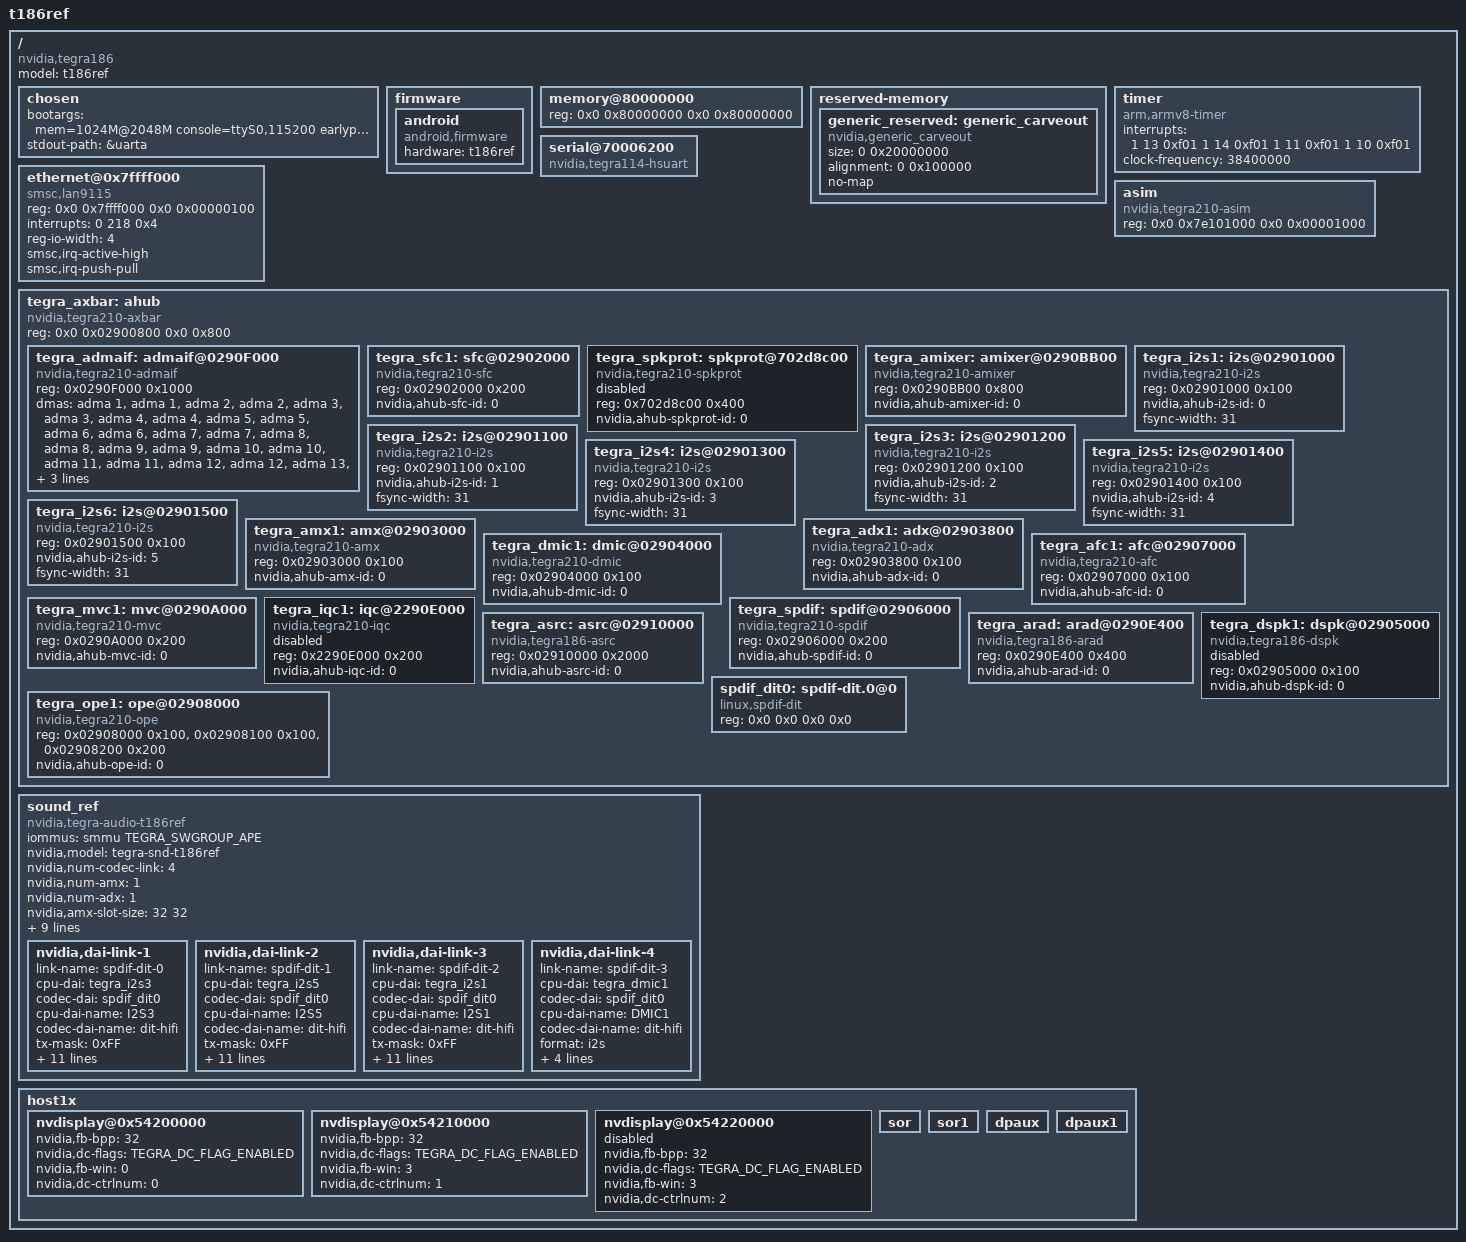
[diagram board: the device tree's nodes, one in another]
/*
 * arch/arm64/boot/dts/tegra186-sim-private.dts
 *
 * Copyright (c) 2014-2015, NVIDIA CORPORATION.  All rights reserved.
 *
 * This program is free software; you can redistribute it and/or modify
 * it under the terms of the GNU General Public License as published by
 * the Free Software Foundation; version 2 of the License.
 *
 * This program is distributed in the hope that it will be useful, but WITHOUT
 * ANY WARRANTY; without even the implied warranty of MERCHANTABILITY or
 * FITNESS FOR A PARTICULAR PURPOSE.  See the GNU General Public License for
 * more details.
 *
 * You should have received a copy of the GNU General Public License along
 * with this program; if not, write to the Free Software Foundation, Inc.,
 * 51 Franklin Street, Fifth Floor, Boston, MA  02110-1301, USA.
 *
 */

/dts-v1/;

/memreserve/ 0x80000000 0x00010000;

#include "tegra186.dtsi"
#include "tegra186-cpus-2D4A.dtsi"
#include "panel-sim.dtsi"
#include "tegra186-sim-hdmi.dtsi"
#include "tegra186-sdhci.dtsi"
#include <dt-bindings/sound/tegra-asoc-alt.h>

/ {
	model = "t186ref";
	compatible = "nvidia,tegra186";

	chosen {
		bootargs ="mem=1024M@2048M console=ttyS0,115200 earlyprintk=uart8250-32bit,0x70006000";
		stdout-path = &uarta;
	};

	/* chosen */

	firmware {
		android {
			compatible = "android,firmware";
			hardware = "t186ref";
		};
	};

	memory@80000000 {
		device_type = "memory";
		reg = < 0x0 0x80000000 0x0 0x80000000 >;
	};

	reserved-memory {
		#address-cells = <2>;
		#size-cells = <2>;
		ranges;

		generic_reserved: generic_carveout {
			compatible = "nvidia,generic_carveout";
			size = <0 0x20000000>;
			alignment = <0 0x100000>;
			no-map;
		};
	};

	timer {
		compatible = "arm,armv8-timer";
		interrupts = <1 13 0xf01
			      1 14 0xf01
			      1 11 0xf01
			      1 10 0xf01>;
		clock-frequency = <38400000>;
	};

	serial@70006200 {
		compatible = "nvidia,tegra114-hsuart";
		status = "okay";
	};

	ethernet@0x7ffff000 {
		compatible = "smsc,lan9115";
		reg = < 0x0 0x7ffff000 0x0 0x00000100 >;
		interrupts = <0 218 0x4>;
		reg-io-width = <4>;
		smsc,irq-active-high;
		smsc,irq-push-pull;
	};

	asim {
		compatible = "nvidia,tegra210-asim";
		reg = < 0x0 0x7e101000 0x0 0x00001000 >;
	};

	tegra_axbar: ahub {
		compatible = "nvidia,tegra210-axbar";
		reg = <0x0 0x02900800 0x0 0x800>;
		status = "okay";

		#address-cells = <1>;
		#size-cells = <1>;
		ranges = <0x02900000 0x0 0x02900000 0x00020000>;

		tegra_admaif: admaif@0290F000 {
			compatible = "nvidia,tegra210-admaif";
			reg = <0x0290F000 0x1000>;
			dmas = <&adma 1>, <&adma 1>, <&adma 2>, <&adma 2>,
				<&adma 3>, <&adma 3>, <&adma 4>, <&adma 4>,
				<&adma 5>, <&adma 5>, <&adma 6>, <&adma 6>,
				<&adma 7>, <&adma 7>, <&adma 8>, <&adma 8>,
				<&adma 9>, <&adma 9>, <&adma 10>, <&adma 10>,
				<&adma 11>, <&adma 11>, <&adma 12>, <&adma 12>,
				<&adma 13>, <&adma 13>, <&adma 14>, <&adma 14>,
				<&adma 15>, <&adma 15>, <&adma 16>, <&adma 16>,
				<&adma 17>, <&adma 17>, <&adma 18>, <&adma 18>,
				<&adma 19>, <&adma 19>, <&adma 20>, <&adma 20>;
			dma-names = "rx1", "tx1", "rx2", "tx2", "rx3", "tx3",
				"rx4", "tx4", "rx5", "tx5", "rx6", "tx6",
				"rx7", "tx7", "rx8", "tx8", "rx9", "tx9",
				"rx10", "tx10", "rx11", "tx11", "rx12", "tx12",
				"rx13", "tx13",	"rx14", "tx14", "rx15", "tx15",
				"rx16", "tx16",	"rx17", "tx17", "rx18", "tx18",
				"rx19", "tx19",	"rx20", "tx20";
			status = "okay";
		};

		tegra_sfc1: sfc@02902000 {
			compatible = "nvidia,tegra210-sfc";
			reg = <0x02902000 0x200>;
			nvidia,ahub-sfc-id = <0>;
			status = "okay";
		};

		tegra_spkprot: spkprot@702d8c00 {
			compatible = "nvidia,tegra210-spkprot";
			reg = <0x702d8c00 0x400>;
			nvidia,ahub-spkprot-id = <0>;
			status = "disabled";
		};

		tegra_amixer: amixer@0290BB00 {
			compatible = "nvidia,tegra210-amixer";
			reg = <0x0290BB00 0x800>;
			nvidia,ahub-amixer-id = <0>;
			status = "okay";
		};

		tegra_i2s1: i2s@02901000 {
			compatible = "nvidia,tegra210-i2s";
			reg = <0x02901000 0x100>;
			nvidia,ahub-i2s-id = <0>;
			status = "okay";
		};

		tegra_i2s2: i2s@02901100 {
			compatible = "nvidia,tegra210-i2s";
			reg = <0x02901100 0x100>;
			nvidia,ahub-i2s-id = <1>;
			status = "okay";
		};

		tegra_i2s3: i2s@02901200 {
			compatible = "nvidia,tegra210-i2s";
			reg = <0x02901200 0x100>;
			nvidia,ahub-i2s-id = <2>;
			status = "okay";
		};

		tegra_i2s4: i2s@02901300 {
			compatible = "nvidia,tegra210-i2s";
			reg = <0x02901300 0x100>;
			nvidia,ahub-i2s-id = <3>;
			status = "okay";
		};

		tegra_i2s5: i2s@02901400 {
			compatible = "nvidia,tegra210-i2s";
			reg = <0x02901400 0x100>;
			nvidia,ahub-i2s-id = <4>;
			status = "okay";
		};

		tegra_i2s6: i2s@02901500 {
			compatible = "nvidia,tegra210-i2s";
			reg = <0x02901500 0x100>;
			nvidia,ahub-i2s-id = <5>;
			status = "okay";
		};

		tegra_amx1: amx@02903000 {
			compatible = "nvidia,tegra210-amx";
			reg = <0x02903000 0x100>;
			nvidia,ahub-amx-id = <0>;
			status = "okay";
		};

		tegra_adx1: adx@02903800 {
			compatible = "nvidia,tegra210-adx";
			reg = <0x02903800 0x100>;
			nvidia,ahub-adx-id = <0>;
			status = "okay";
		};

		tegra_dmic1: dmic@02904000 {
			compatible = "nvidia,tegra210-dmic";
			reg = <0x02904000 0x100>;
			nvidia,ahub-dmic-id = <0>;
			status = "okay";
		};

		tegra_afc1: afc@02907000 {
			compatible = "nvidia,tegra210-afc";
			reg = <0x02907000 0x100>;
			nvidia,ahub-afc-id = <0>;
			status = "okay";
		};

		tegra_mvc1: mvc@0290A000 {
			compatible = "nvidia,tegra210-mvc";
			reg = <0x0290A000 0x200>;
			nvidia,ahub-mvc-id = <0>;
			status = "okay";
		};

		tegra_spdif: spdif@02906000 {
			compatible = "nvidia,tegra210-spdif";
			reg = <0x02906000 0x200>;
			nvidia,ahub-spdif-id = <0>;
			status = "okay";
		};

		tegra_iqc1: iqc@2290E000 {
			compatible = "nvidia,tegra210-iqc";
			reg = <0x2290E000 0x200>;
			nvidia,ahub-iqc-id = <0>;
			status = "disabled";
		};

		tegra_asrc: asrc@02910000 {
			compatible = "nvidia,tegra186-asrc";
			reg = <0x02910000 0x2000>;
			nvidia,ahub-asrc-id = <0>;
			status = "okay";
		};

		tegra_arad: arad@0290E400 {
			compatible = "nvidia,tegra186-arad";
			reg = <0x0290E400 0x400>;
			nvidia,ahub-arad-id = <0>;
			status = "okay";
		};

		tegra_ope1: ope@02908000 {
			compatible = "nvidia,tegra210-ope";
			reg = <0x02908000 0x100>,
			      <0x02908100 0x100>,
			      <0x02908200 0x200>;
			nvidia,ahub-ope-id = <0>;
			status = "okay";
		};

		tegra_dspk1: dspk@02905000 {
			compatible = "nvidia,tegra186-dspk";
			reg = <0x02905000 0x100>;
			nvidia,ahub-dspk-id = <0>;
			status = "disabled";
		};

		spdif_dit0: spdif-dit.0@0 {
			compatible = "linux,spdif-dit";
			reg = <0x0 0x0 0x0 0x0>;
			status = "okay";
		};
	};

	ahub {
		i2s@02901000 {
			fsync-width = <31>;
		};

		i2s@02901100 {
			fsync-width = <31>;
		};

		i2s@02901200 {
			fsync-width = <31>;
		};

		i2s@02901300 {
			fsync-width = <31>;
		};

		i2s@02901400 {
			fsync-width = <31>;
		};

		i2s@02901500 {
			fsync-width = <31>;
		};
	};

	sound_ref {
		compatible = "nvidia,tegra-audio-t186ref";
		iommus = <&smmu TEGRA_SWGROUP_APE>;
		nvidia,model = "tegra-snd-t186ref";
		nvidia,num-codec-link = <4>;
		nvidia,num-amx = <1>;
		nvidia,num-adx = <1>;
		nvidia,amx-slot-size = <32 32>;
		nvidia,adx-slot-size = <32 32>;
		nvidia,addr-max9485 = <0>;
		nvidia,amx-slot-map = <
			/* jack 0 */
			TDM_SLOT_MAP(0, 0, 0)
			TDM_SLOT_MAP(0, 0, 0)
			TDM_SLOT_MAP(0, 1, 0)
			TDM_SLOT_MAP(0, 1, 1)
			TDM_SLOT_MAP(0, 0, 0)
			TDM_SLOT_MAP(0, 0, 0)
			TDM_SLOT_MAP(0, 2, 0)
			TDM_SLOT_MAP(0, 2, 1)
			/* jack 1 */
			TDM_SLOT_MAP(0, 0, 0)
			TDM_SLOT_MAP(0, 0, 0)
			TDM_SLOT_MAP(1, 1, 0)
			TDM_SLOT_MAP(1, 1, 1)
			TDM_SLOT_MAP(0, 0, 0)
			TDM_SLOT_MAP(0, 0, 0)
			TDM_SLOT_MAP(1, 2, 0)
			TDM_SLOT_MAP(1, 2, 1)
			/* jack 2 */
			TDM_SLOT_MAP(0, 0, 0)
			TDM_SLOT_MAP(0, 0, 0)
			TDM_SLOT_MAP(2, 1, 0)
			TDM_SLOT_MAP(2, 1, 1)
			TDM_SLOT_MAP(0, 0, 0)
			TDM_SLOT_MAP(0, 0, 0)
			TDM_SLOT_MAP(2, 2, 0)
			TDM_SLOT_MAP(2, 2, 1)
			/* jack 3 */
			TDM_SLOT_MAP(0, 0, 0)
			TDM_SLOT_MAP(0, 0, 0)
			TDM_SLOT_MAP(3, 1, 0)
			TDM_SLOT_MAP(3, 1, 1)
			TDM_SLOT_MAP(0, 0, 0)
			TDM_SLOT_MAP(0, 0, 0)
			TDM_SLOT_MAP(3, 2, 0)
			TDM_SLOT_MAP(3, 2, 1)>;
		nvidia,adx-slot-map = <
			/* jack 0 */
			TDM_SLOT_MAP(0, 0, 0)
			TDM_SLOT_MAP(0, 0, 0)
			TDM_SLOT_MAP(0, 1, 0)
			TDM_SLOT_MAP(0, 1, 1)
			TDM_SLOT_MAP(0, 0, 0)
			TDM_SLOT_MAP(0, 0, 0)
			TDM_SLOT_MAP(0, 2, 0)
			TDM_SLOT_MAP(0, 2, 1)
			/* jack 1 */
			TDM_SLOT_MAP(0, 0, 0)
			TDM_SLOT_MAP(0, 0, 0)
			TDM_SLOT_MAP(1, 1, 0)
			TDM_SLOT_MAP(1, 1, 1)
			TDM_SLOT_MAP(0, 0, 0)
			TDM_SLOT_MAP(0, 0, 0)
			TDM_SLOT_MAP(1, 2, 0)
			TDM_SLOT_MAP(1, 2, 1)
			/* jack 2 */
			TDM_SLOT_MAP(0, 0, 0)
			TDM_SLOT_MAP(0, 0, 0)
			TDM_SLOT_MAP(2, 1, 0)
			TDM_SLOT_MAP(2, 1, 1)
			TDM_SLOT_MAP(0, 0, 0)
			TDM_SLOT_MAP(0, 0, 0)
			TDM_SLOT_MAP(2, 2, 0)
			TDM_SLOT_MAP(2, 2, 1)
			/* jack 3 */
			TDM_SLOT_MAP(0, 0, 0)
			TDM_SLOT_MAP(0, 0, 0)
			TDM_SLOT_MAP(3, 1, 0)
			TDM_SLOT_MAP(3, 1, 1)
			TDM_SLOT_MAP(0, 0, 0)
			TDM_SLOT_MAP(0, 0, 0)
			TDM_SLOT_MAP(3, 2, 0)
			TDM_SLOT_MAP(3, 2, 1)>;

        nvidia,audio-routing =
                "Headphone-x",  "x OUT",
                "x IN", "LineIn-x";

        nvidia,xbar = <&tegra_axbar>;

		nvidia,dai-link-1 {
			link-name = "spdif-dit-0";
			cpu-dai = <&tegra_i2s3>;
			codec-dai = <&spdif_dit0>;
			cpu-dai-name = "I2S3";
			codec-dai-name = "dit-hifi";
			tx-mask = <0xFF>;
			rx-mask = <0xFF>;
			format = "dsp_a";
			bitclock-slave;
			frame-slave;
			bitclock-noninversion;
			frame-noninversion;
			bit-format = "s32_le";
			bclk_ratio = <1>;
			srate = <48000>;
			num-channel = <8>;
			name-prefix = "x";
		};
		nvidia,dai-link-2 {
			link-name = "spdif-dit-1";
			cpu-dai = <&tegra_i2s5>;
			codec-dai = <&spdif_dit0>;
			cpu-dai-name = "I2S5";
			codec-dai-name = "dit-hifi";
			tx-mask = <0xFF>;
			rx-mask = <0xFF>;
			format = "i2s";
			bitclock-slave;
			frame-slave;
			bitclock-noninversion;
			frame-noninversion;
			bit-format = "s16_le";
			bclk_ratio = <2>;
			srate = <48000>;
			num-channel = <2>;
			name-prefix = "x";
		};
		nvidia,dai-link-3 {
			link-name = "spdif-dit-2";
			cpu-dai = <&tegra_i2s1>;
			codec-dai = <&spdif_dit0>;
			cpu-dai-name = "I2S1";
			codec-dai-name = "dit-hifi";
			tx-mask = <0xFF>;
			rx-mask = <0xFF>;
			format = "i2s";
			bitclock-slave;
			frame-slave;
			bitclock-noninversion;
			frame-noninversion;
			bit-format = "s16_le";
			bclk_ratio = <2>;
			srate = <8000>;
			num-channel = <2>;
			name-prefix = "x";
		};
		nvidia,dai-link-4 {
			link-name = "spdif-dit-3";
			cpu-dai = <&tegra_dmic1>;
			codec-dai = <&spdif_dit0>;
			cpu-dai-name = "DMIC1";
			codec-dai-name = "dit-hifi";
			format = "i2s";
			bit-format = "s16_le";
			srate = <48000>;
			num-channel = <2>;
			name-prefix = "dmic-x";
		};
	};


	host1x {

		nvdisplay@0x54200000 {
			status = "okay";
			nvidia,fb-bpp = <32>; /* bits per pixel */
			nvidia,dc-flags = <TEGRA_DC_FLAG_ENABLED>;
			nvidia,fb-win = <0>;
			nvidia,dc-ctrlnum = <0>;
		};

		nvdisplay@0x54210000 {
			status = "okay";
			nvidia,fb-bpp = <32>; /* bits per pixel */
			nvidia,dc-flags = <TEGRA_DC_FLAG_ENABLED>;
			nvidia,fb-win = <3>;
			nvidia,dc-ctrlnum = <1>;
		};

		nvdisplay@0x54220000 {
			status = "disabled";
			nvidia,fb-bpp = <32>; /* bits per pixel */
			nvidia,dc-flags = <TEGRA_DC_FLAG_ENABLED>;
			nvidia,fb-win = <3>;
			nvidia,dc-ctrlnum = <2>;
		};

		sor {
			status = "okay";
		};

		sor1 {
			status = "okay";
		};

		dpaux {
			status = "okay";
		};

		dpaux1 {
			status = "okay";
		};
	};
};
